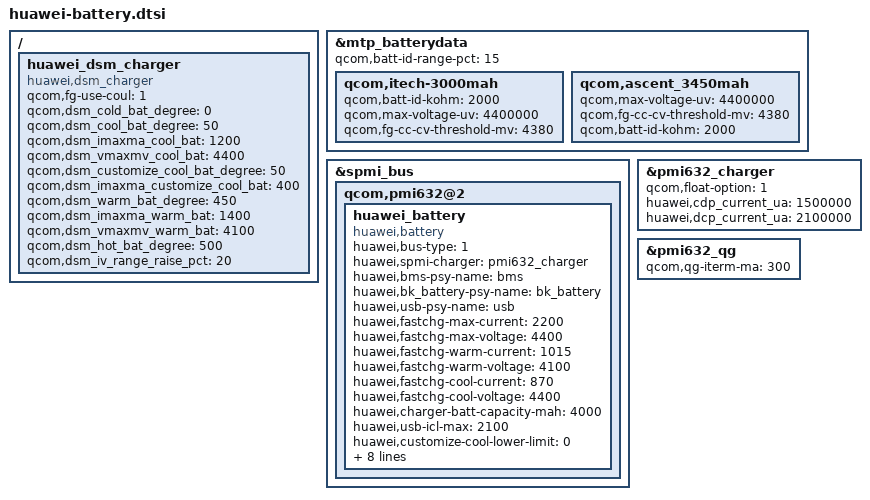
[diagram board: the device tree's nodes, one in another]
 &mtp_batterydata {
     qcom,batt-id-range-pct = <15>;

     qcom,itech-3000mah {
         qcom,batt-id-kohm = <2000>;
         qcom,max-voltage-uv = <4400000>;
         qcom,fg-cc-cv-threshold-mv = <4380>;
     };
     qcom,ascent_3450mah {
	/* Ascent_wConn_3450mAh_Fresh_averaged_MasterSlave_Feb7th2018 */
	qcom,max-voltage-uv = <4400000>;
	qcom,fg-cc-cv-threshold-mv = <4380>;
	qcom,batt-id-kohm = <2000>;
	};
     #include "../HB406689ECW_Desay_ATL_4v4_4000mAh.dtsi"
	 #include "../HB406689ECW_muRata_Scud_4v4_4000mAh.dtsi"
     #include "../Huawei_default_battery.dtsi"
};

&spmi_bus {
		qcom,pmi632@2 {
          huawei_battery: huawei_battery {
                  compatible = "huawei,battery";
                  status = "ok";
                  huawei,bus-type = <1>;
                  huawei,spmi-charger = <&pmi632_charger>;
                  huawei,bms-psy-name = "bms";
                  huawei,bk_battery-psy-name = "bk_battery";
                  huawei,usb-psy-name = "usb";
                  huawei,fastchg-max-current = <2200>;
                  huawei,fastchg-max-voltage = <4400>;
                  huawei,fastchg-warm-current = <1015>;
                  huawei,fastchg-warm-voltage = <4100>;
                  huawei,fastchg-cool-current = <870>;
                  huawei,fastchg-cool-voltage = <4400>;
                  huawei,charger-batt-capacity-mah = <4000>;
                  huawei,usb-icl-max = <2100>;
                  huawei,customize-cool-lower-limit = <0>;
                  huawei,customize-cool-upper-limit = <50>;
                  huawei,fastchg-current-customize-cool-ma = <500>;
                  huawei,disable-huawei-func;
                  huawei,jeita-hardware-charge-disable;
                  huawei,ibus-detect-disable;
				  huawei,dump-regs-num = <50>;
				  huawei,dump-regs = <
				  0x1006 0x1007 0x1009 0x100B 0x100C
				  0x100D 0x100E 0x1010 0x1040 0x1042
				  0x1050 0x1051 0x1061 0x1062 0x1063
				  0x1066 0x1070 0x1075 0x1076 0x107D
				  0x1086 0x1090 0x1091 0x1092 0x1093
				  0x1094 0x1095 0x1096 0x1097 0x1098
				  0x1099 0x109A 0x109B 0x109C 0x109D
				  0x109E 0x109F 0x10A0 0x110A 0x110B
				  0x110D 0x1140 0x1152 0x1286 0x1308
				  0x1310 0x1363 0x1366 0x1370 0x1380
				  >;
          	};
		  };
};
/{
	huawei_dsm_charger: huawei_dsm_charger{
		compatible = "huawei,dsm_charger";
		status = "ok";
		qcom,fg-use-coul = <1>;
		qcom,dsm_cold_bat_degree = <0>;
		qcom,dsm_cool_bat_degree = <50>;
		qcom,dsm_imaxma_cool_bat = <1200>;
		qcom,dsm_vmaxmv_cool_bat = <4400>;
		qcom,dsm_customize_cool_bat_degree = <50>;
		qcom,dsm_imaxma_customize_cool_bat = <400>;
		qcom,dsm_warm_bat_degree = <450>;
		qcom,dsm_imaxma_warm_bat = <1400>;
		qcom,dsm_vmaxmv_warm_bat = <4100>;
		qcom,dsm_hot_bat_degree = <500>;
		qcom,dsm_iv_range_raise_pct = <20>;
	};
};
&pmi632_charger{
		qcom,float-option = <1>;
		huawei,cdp_current_ua = <1500000>;
		huawei,dcp_current_ua = <2100000>;
};
&pmi632_qg {
	qcom,qg-iterm-ma = <300>;
};
